# GD32E53x register map
File version: 1.0
CPU: CM33 r0p4, little endian, MPU, FPU, 4 interrupt priority bits
Registers are 32-bit, read-write, reset 0x0 unless marked. A register's access mark holds for its fields unless they carry their own. Offsets are from the block's base; [hi:lo] are bit positions; {n}, {i} and the like mark numbered series; 'fields as' and 'values as' point back to an identical list.

## TRIGSEL — Trigger selection controller
Base 0x40019000
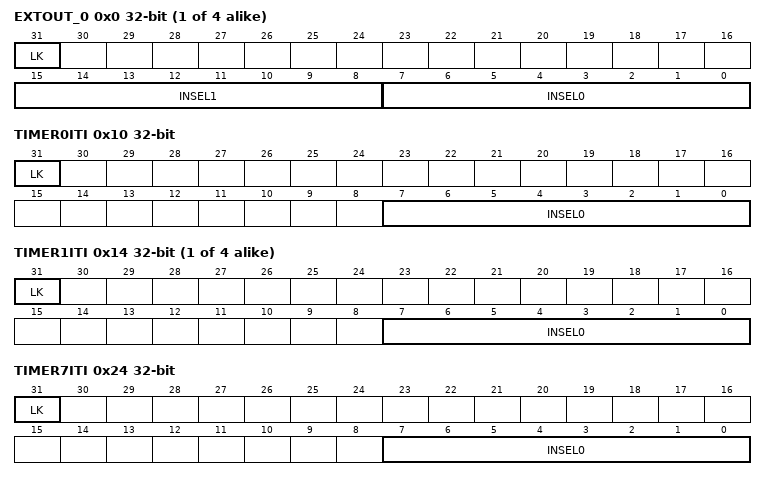
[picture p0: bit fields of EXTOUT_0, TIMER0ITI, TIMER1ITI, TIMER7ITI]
{0x0+4i} EXTOUT_{i} (i=0..3) — Trigger selection for EXTOUT register {i}
  [31] LK — TRIGSEL register lock.
  [15:8] INSEL1 — Trigger input source selection for output1
  [7:0] INSEL0 — Trigger input source selection for output0
0x10 TIMER0ITI — Trigger selection for TIMER0_ETI register
  [31] LK — TRIGSEL register lock.
  [7:0] INSEL0 — Trigger input source selection for output0
{0x10+4i} TIMER{i}ITI (i=1..4) — Trigger selection for TIMER{i}_ITI register
  fields as TIMER0ITI
0x24 TIMER7ITI — Trigger selection for TIMER7_ITI register
  fields as TIMER0ITI
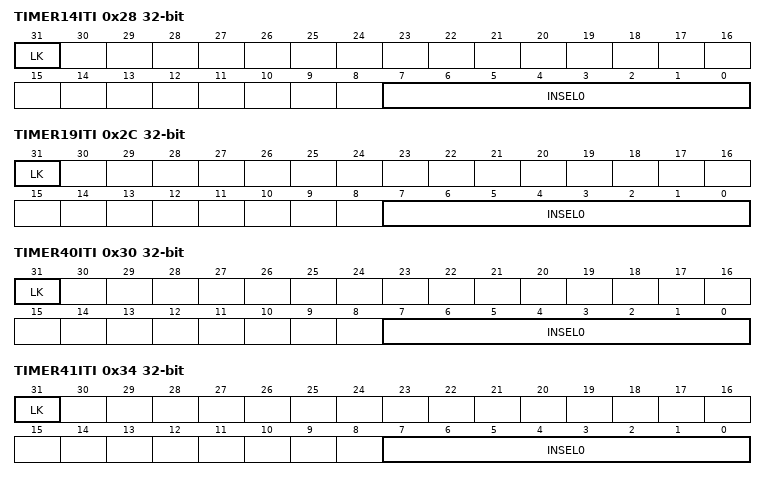
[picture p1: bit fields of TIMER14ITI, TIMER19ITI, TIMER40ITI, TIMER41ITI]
0x28 TIMER14ITI — Trigger selection for TIMER14_ITI register
  fields as TIMER0ITI
0x2C TIMER19ITI — Trigger selection for TIMER19_ITI register
  fields as TIMER0ITI
0x30 TIMER40ITI — Trigger selection for TIMER40_ITI register
  fields as TIMER0ITI
0x34 TIMER41ITI — Trigger selection for TIMER41_ITI register
  fields as TIMER0ITI
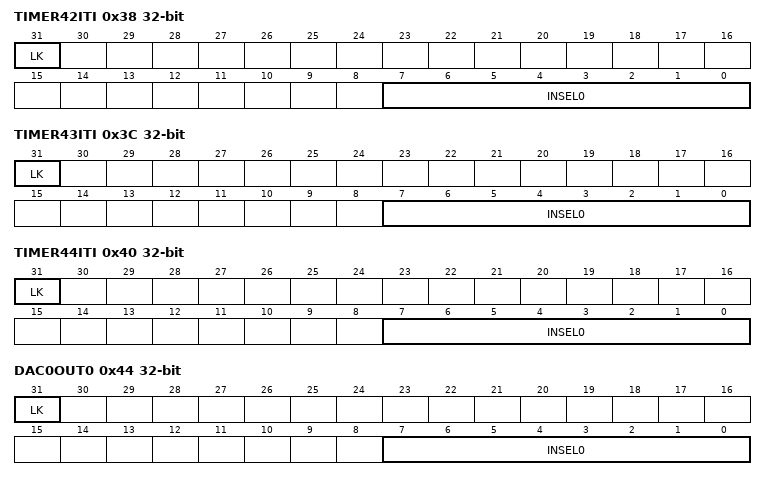
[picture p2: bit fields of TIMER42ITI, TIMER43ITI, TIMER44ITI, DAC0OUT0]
0x38 TIMER42ITI — Trigger selection for TIMER42_ITI register
  fields as TIMER0ITI
0x3C TIMER43ITI — Trigger selection for TIMER43_ITI register
  fields as TIMER0ITI
0x40 TIMER44ITI — Trigger selection for TIMER44_ITI register
  fields as TIMER0ITI
0x44 DAC0OUT0 — Trigger selection for DAC register0
  fields as TIMER0ITI
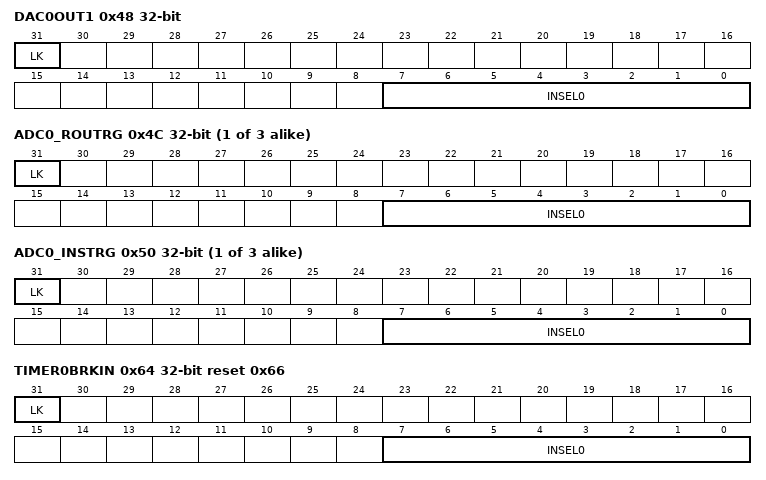
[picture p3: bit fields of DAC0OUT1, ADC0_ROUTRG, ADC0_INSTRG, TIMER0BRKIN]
0x48 DAC0OUT1 — Trigger selection for DAC register1
  fields as TIMER0ITI
{0x4C+8i} ADC{i}_ROUTRG (i=0..2) — Trigger selection for ADC{i}_ROUTRG register
  fields as TIMER0ITI
{0x50+8i} ADC{i}_INSTRG (i=0..2) — Trigger selection for ADC{i}_INSTRG register
  fields as TIMER0ITI
0x64 TIMER0BRKIN reset 0x66 — Trigger selection for TIMER0_BRKIN register
  [31] LK — TRIGSEL register lock.
  [7:0] INSEL0 — Trigger input source selection for TIMER0_BRKIN
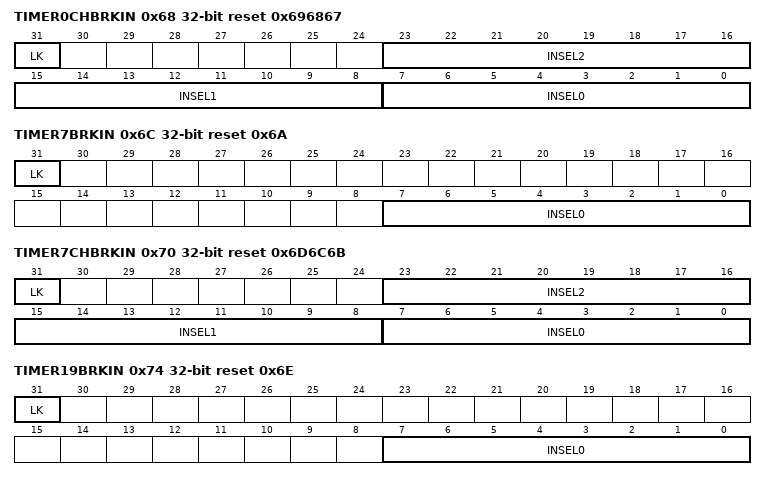
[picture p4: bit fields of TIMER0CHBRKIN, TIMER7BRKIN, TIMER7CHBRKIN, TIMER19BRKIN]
0x68 TIMER0CHBRKIN reset 0x696867 — Trigger selection for TIMER0_CHBRKIN register
  [31] LK — TRIGSEL register lock.
  [23:16] INSEL2 — Trigger input source selection for TIMER0_CH2BRKIN.
  [15:8] INSEL1 — Trigger input source selection for TIMER0_CH1BRKIN
  [7:0] INSEL0 — Trigger input source selection for TIMER0_CH0BRKIN
0x6C TIMER7BRKIN reset 0x6A — Trigger selection for TIMER7_BRKIN register
  [31] LK — TRIGSEL register lock.
  [7:0] INSEL0 — Trigger input source selection for TIMER7_BRKIN
0x70 TIMER7CHBRKIN reset 0x6D6C6B — Trigger selection for TIMER7_CHBRKIN register
  [31] LK — TRIGSEL register lock.
  [23:16] INSEL2 — Trigger input source selection for TIMER7_CH2BRKIN.
  [15:8] INSEL1 — Trigger input source selection for TIMER7_CH1BRKIN
  [7:0] INSEL0 — Trigger input source selection for TIMER7_CH0BRKIN
0x74 TIMER19BRKIN reset 0x6E — Trigger selection for TIMER19_BRKIN register
  [31] LK — TRIGSEL register lock.
  [7:0] INSEL0 — Trigger input source selection for TIMER19_BRKIN
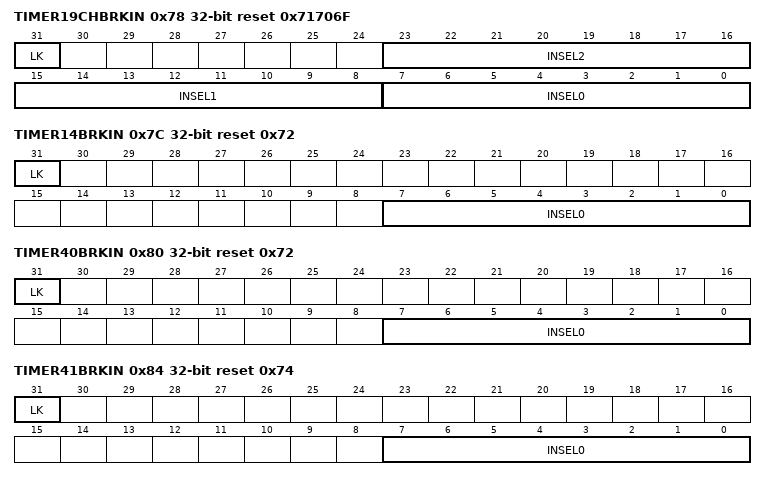
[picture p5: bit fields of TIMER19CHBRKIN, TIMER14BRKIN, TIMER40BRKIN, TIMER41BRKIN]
0x78 TIMER19CHBRKIN reset 0x71706F — Trigger selection for TIMER19_CHBRKIN register
  [31] LK — TRIGSEL register lock.
  [23:16] INSEL2 — Trigger input source selection for TIMER19_CH2BRKIN.
  [15:8] INSEL1 — Trigger input source selection for TIMER19_CH1BRKIN
  [7:0] INSEL0 — Trigger input source selection for TIMER19_CH0BRKIN
0x7C TIMER14BRKIN reset 0x72 — Trigger selection for TIMER14_BRKIN register
  [31] LK — TRIGSEL register lock.
  [7:0] INSEL0 — Trigger input source selection for TIMER14_BRKIN.
0x80 TIMER40BRKIN reset 0x72 — Trigger selection for TIMER40_BRKIN register
  [31] LK — TRIGSEL register lock.
  [7:0] INSEL0 — Trigger input source selection for TIMER40_BRKIN.
0x84 TIMER41BRKIN reset 0x74 — Trigger selection for TIMER41_BRKIN register
  [31] LK — TRIGSEL register lock.
  [7:0] INSEL0 — Trigger input source selection for TIMER41_BRKIN.
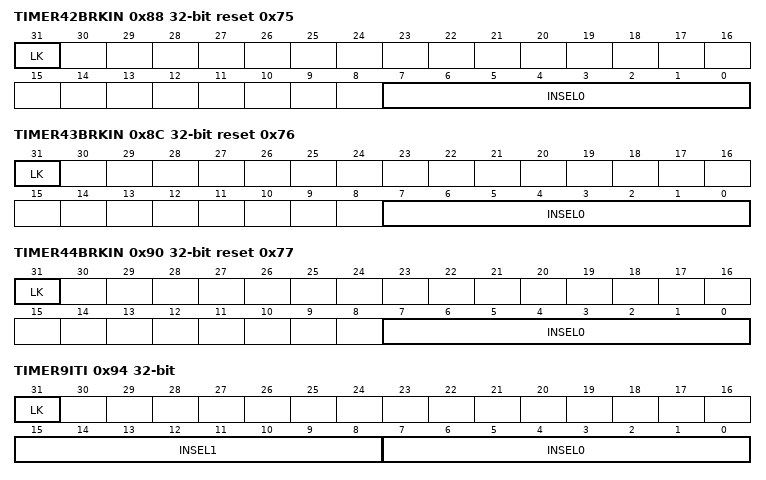
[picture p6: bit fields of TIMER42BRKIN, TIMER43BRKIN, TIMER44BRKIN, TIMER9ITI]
0x88 TIMER42BRKIN reset 0x75 — Trigger selection for TIMER42_BRKIN register
  [31] LK — TRIGSEL register lock.
  [7:0] INSEL0 — Trigger input source selection for TIMER42_BRKIN.
0x8C TIMER43BRKIN reset 0x76 — Trigger selection for TIMER43_BRKIN register
  [31] LK — TRIGSEL register lock.
  [7:0] INSEL0 — Trigger input source selection for TIMER43_BRKIN.
0x90 TIMER44BRKIN reset 0x77 — Trigger selection for TIMER44_BRKIN register
  [31] LK — TRIGSEL register lock.
  [7:0] INSEL0 — Trigger input source selection for TIMER44_BRKIN.
0x94 TIMER9ITI — Trigger selection for TIMER9_ITI register
  [31] LK — TRIGSEL register lock.
  [15:8] INSEL1 — Trigger input source selection for TIMER9_ITI14
  [7:0] INSEL0 — Trigger input source selection for TIMER9_ITI0
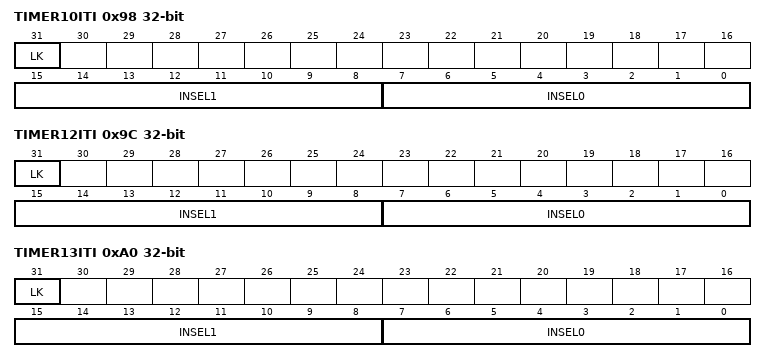
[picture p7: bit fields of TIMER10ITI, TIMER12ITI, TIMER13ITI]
0x98 TIMER10ITI — Trigger selection for TIMER10_ITI register
  [31] LK — TRIGSEL register lock.
  [15:8] INSEL1 — Trigger input source selection for TIMER10_ITI14
  [7:0] INSEL0 — Trigger input source selection for TIMER10_ITI0
0x9C TIMER12ITI — Trigger selection for TIMER12_ITI register
  [31] LK — TRIGSEL register lock.
  [15:8] INSEL1 — Trigger input source selection for TIMER12_ITI14
  [7:0] INSEL0 — Trigger input source selection for TIMER12_ITI0
0xA0 TIMER13ITI — Trigger selection for TIMER13_ITI register
  [31] LK — TRIGSEL register lock.
  [15:8] INSEL1 — Trigger input source selection for TIMER13_ITI14
  [7:0] INSEL0 — Trigger input source selection for TIMER13_ITI0
